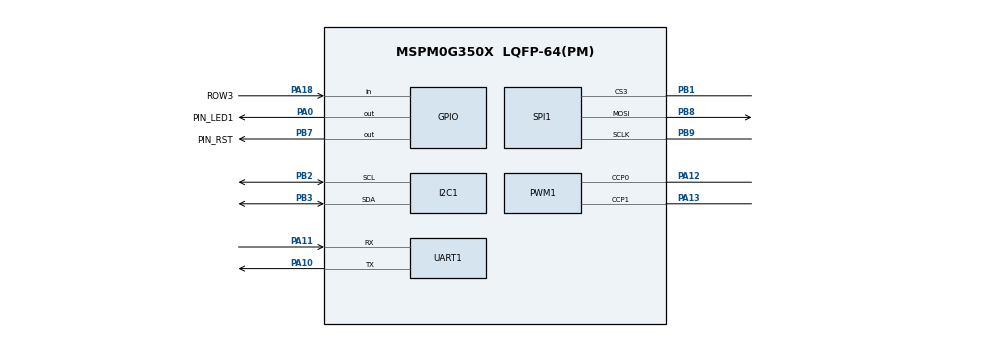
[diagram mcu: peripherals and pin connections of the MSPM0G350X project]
/**
 * @cliArgs --device "MSPM0G350X" --package "LQFP-64(PM)" --part "Default" --product "mspm0_sdk@2.01.00.03"
 * @versions {"tool":"1.20.0+3587"}
 */

/**
 * Import the modules used in this configuration.
 */
const GPIO   = scripting.addModule("/ti/driverlib/GPIO", {}, false);
const GPIO1  = GPIO.addInstance();
const GPIO2  = GPIO.addInstance();
const GPIO3  = GPIO.addInstance();
const GPIO4  = GPIO.addInstance();
const GPIO5  = GPIO.addInstance();
const GPIO6  = GPIO.addInstance();
const GPIO7  = GPIO.addInstance();
const GPIO8  = GPIO.addInstance();
const GPIO9  = GPIO.addInstance();
const GPIO10 = GPIO.addInstance();
const GPIO11 = GPIO.addInstance();
const I2C    = scripting.addModule("/ti/driverlib/I2C", {}, false);
const I2C1   = I2C.addInstance();
const PWM    = scripting.addModule("/ti/driverlib/PWM", {}, false);
const PWM1   = PWM.addInstance();
const SPI    = scripting.addModule("/ti/driverlib/SPI", {}, false);
const SPI1   = SPI.addInstance();
const SYSCTL = scripting.addModule("/ti/driverlib/SYSCTL");
const TIMER  = scripting.addModule("/ti/driverlib/TIMER", {}, false);
const TIMER1 = TIMER.addInstance();
const TIMER2 = TIMER.addInstance();
const TIMER3 = TIMER.addInstance();
const TIMER4 = TIMER.addInstance();
const TIMER5 = TIMER.addInstance();
const UART   = scripting.addModule("/ti/driverlib/UART", {}, false);
const UART1  = UART.addInstance();

/**
 * Write custom configuration values to the imported modules.
 */
GPIO1.$name                              = "GPIO_LED_2";
GPIO1.port                               = "PORTB";
GPIO1.associatedPins.create(3);
GPIO1.associatedPins[0].internalResistor = "PULL_UP";
GPIO1.associatedPins[0].assignedPin      = "27";
GPIO1.associatedPins[0].$name            = "PIN_LED_GREEN";
GPIO1.associatedPins[1].$name            = "PIN_LED_BLUE";
GPIO1.associatedPins[1].assignedPin      = "22";
GPIO1.associatedPins[2].$name            = "PIN_LED_RED";
GPIO1.associatedPins[2].assignedPin      = "26";

const Board = scripting.addModule("/ti/driverlib/Board", {}, false);

GPIO2.$name                          = "GPIO_CTRL";
GPIO2.associatedPins.create(2);
GPIO2.associatedPins[0].$name        = "PIN_RST";
GPIO2.associatedPins[0].initialValue = "SET";
GPIO2.associatedPins[0].assignedPort = "PORTB";
GPIO2.associatedPins[0].assignedPin  = "7";
GPIO2.associatedPins[0].pin.$assign  = "PB7";
GPIO2.associatedPins[1].$name        = "DC";
GPIO2.associatedPins[1].assignedPort = "PORTB";
GPIO2.associatedPins[1].assignedPin  = "6";

GPIO3.$name                          = "GPIO_BEEP";
GPIO3.port                           = "PORTB";
GPIO3.associatedPins[0].$name        = "PIN_0";
GPIO3.associatedPins[0].initialValue = "SET";
GPIO3.associatedPins[0].assignedPin  = "19";

GPIO4.port                               = "PORTB";
GPIO4.$name                              = "GPIO_BUTTON2";
GPIO4.associatedPins[0].assignedPin      = "21";
GPIO4.associatedPins[0].direction        = "INPUT";
GPIO4.associatedPins[0].$name            = "PIN_S2";
GPIO4.associatedPins[0].internalResistor = "PULL_UP";

GPIO5.$name                          = "GPIO_Encoder";
GPIO5.associatedPins.create(4);
GPIO5.associatedPins[0].direction    = "INPUT";
GPIO5.associatedPins[0].assignedPort = "PORTA";
GPIO5.associatedPins[0].interruptEn  = true;
GPIO5.associatedPins[0].polarity     = "RISE";
GPIO5.associatedPins[0].assignedPin  = "15";
GPIO5.associatedPins[0].$name        = "PIN_Forward_Right_A";
GPIO5.associatedPins[1].direction    = "INPUT";
GPIO5.associatedPins[1].assignedPort = "PORTA";
GPIO5.associatedPins[1].$name        = "PIN_Forward_Right_B";
GPIO5.associatedPins[1].assignedPin  = "22";
GPIO5.associatedPins[2].direction    = "INPUT";
GPIO5.associatedPins[2].assignedPort = "PORTA";
GPIO5.associatedPins[2].assignedPin  = "28";
GPIO5.associatedPins[2].interruptEn  = true;
GPIO5.associatedPins[2].polarity     = "RISE";
GPIO5.associatedPins[2].$name        = "PIN_Forward_Left_A";
GPIO5.associatedPins[3].direction    = "INPUT";
GPIO5.associatedPins[3].assignedPort = "PORTA";
GPIO5.associatedPins[3].assignedPin  = "31";
GPIO5.associatedPins[3].$name        = "PIN_Forward_Left_B";

GPIO6.$name                         = "GPIO_MOTOR";
GPIO6.port                          = "PORTB";
GPIO6.associatedPins.create(4);
GPIO6.associatedPins[0].$name       = "PIN_AIN1";
GPIO6.associatedPins[0].assignedPin = "0";
GPIO6.associatedPins[1].$name       = "PIN_AIN2";
GPIO6.associatedPins[1].assignedPin = "16";
GPIO6.associatedPins[2].$name       = "PIN_BIN1";
GPIO6.associatedPins[2].assignedPin = "15";
GPIO6.associatedPins[3].$name       = "PIN_BIN2";
GPIO6.associatedPins[3].assignedPin = "17";

GPIO7.$name                         = "GPIO_LED1";
GPIO7.associatedPins[0].$name       = "PIN_LED1";
GPIO7.associatedPins[0].pin.$assign = "PA0";

GPIO8.$name                         = "GPIO_GRAY_SERIAL";
GPIO8.port                          = "PORTA";
GPIO8.associatedPins.create(2);
GPIO8.associatedPins[0].$name       = "PIN_CLK";
GPIO8.associatedPins[0].assignedPin = "24";
GPIO8.associatedPins[1].$name       = "PIN_FOWARD_DAT";
GPIO8.associatedPins[1].direction   = "INPUT";
GPIO8.associatedPins[1].assignedPin = "1";

GPIO9.$name                          = "GPIO_COL";
GPIO9.port                           = "PORTA";
GPIO9.associatedPins.create(4);
GPIO9.associatedPins[0].$name        = "COL1";
GPIO9.associatedPins[0].initialValue = "SET";
GPIO9.associatedPins[0].assignedPin  = "25";
GPIO9.associatedPins[1].$name        = "COL2";
GPIO9.associatedPins[1].initialValue = "SET";
GPIO9.associatedPins[1].assignedPin  = "8";
GPIO9.associatedPins[2].$name        = "COL3";
GPIO9.associatedPins[2].initialValue = "SET";
GPIO9.associatedPins[2].assignedPin  = "26";
GPIO9.associatedPins[3].$name        = "COL4";
GPIO9.associatedPins[3].initialValue = "SET";
GPIO9.associatedPins[3].assignedPin  = "27";

GPIO10.$name                              = "GPIO_ROW";
GPIO10.associatedPins.create(4);
GPIO10.associatedPins[0].$name            = "ROW1";
GPIO10.associatedPins[0].direction        = "INPUT";
GPIO10.associatedPins[0].internalResistor = "PULL_UP";
GPIO10.associatedPins[0].assignedPin      = "24";
GPIO10.associatedPins[0].assignedPort     = "PORTB";
GPIO10.associatedPins[1].$name            = "ROW2";
GPIO10.associatedPins[1].direction        = "INPUT";
GPIO10.associatedPins[1].internalResistor = "PULL_UP";
GPIO10.associatedPins[1].assignedPin      = "18";
GPIO10.associatedPins[1].assignedPort     = "PORTB";
GPIO10.associatedPins[2].$name            = "ROW3";
GPIO10.associatedPins[2].direction        = "INPUT";
GPIO10.associatedPins[2].internalResistor = "PULL_UP";
GPIO10.associatedPins[2].assignedPort     = "PORTA";
GPIO10.associatedPins[2].assignedPin      = "18";
GPIO10.associatedPins[2].pin.$assign      = "PA18";
GPIO10.associatedPins[3].direction        = "INPUT";
GPIO10.associatedPins[3].internalResistor = "PULL_UP";
GPIO10.associatedPins[3].$name            = "ROW4";
GPIO10.associatedPins[3].assignedPort     = "PORTA";
GPIO10.associatedPins[3].assignedPin      = "17";

GPIO11.$name                          = "GPIO_MYLED";
GPIO11.associatedPins[0].$name        = "PIN_LED";
GPIO11.associatedPins[0].assignedPort = "PORTB";
GPIO11.associatedPins[0].assignedPin  = "4";

I2C1.$name                             = "I2C_MPU6050";
I2C1.basicEnableController             = true;
I2C1.intController                     = ["ARBITRATION_LOST","NACK","RXFIFO_TRIGGER","RX_DONE","TX_DONE"];
I2C1.peripheral.sdaPin.$assign         = "PB3";
I2C1.peripheral.sclPin.$assign         = "PB2";
I2C1.sdaPinConfig.hideOutputInversion  = scripting.forceWrite(false);
I2C1.sdaPinConfig.onlyInternalResistor = scripting.forceWrite(false);
I2C1.sdaPinConfig.passedPeripheralType = scripting.forceWrite("Digital");
I2C1.sdaPinConfig.$name                = "ti_driverlib_gpio_GPIOPinGeneric7";
I2C1.sclPinConfig.hideOutputInversion  = scripting.forceWrite(false);
I2C1.sclPinConfig.onlyInternalResistor = scripting.forceWrite(false);
I2C1.sclPinConfig.passedPeripheralType = scripting.forceWrite("Digital");
I2C1.sclPinConfig.$name                = "ti_driverlib_gpio_GPIOPinGeneric8";

PWM1.$name                              = "PWM_MOTOR";
PWM1.timerCount                         = 3200;
PWM1.peripheral.$assign                 = "TIMG0";
PWM1.peripheral.ccp0Pin.$assign         = "PA12";
PWM1.peripheral.ccp1Pin.$assign         = "PA13";
PWM1.PWM_CHANNEL_0.$name                = "ti_driverlib_pwm_PWMTimerCC0";
PWM1.PWM_CHANNEL_1.$name                = "ti_driverlib_pwm_PWMTimerCC1";
PWM1.ccp0PinConfig.$name                = "ti_driverlib_gpio_GPIOPinGeneric2";
PWM1.ccp0PinConfig.direction            = scripting.forceWrite("OUTPUT");
PWM1.ccp0PinConfig.hideOutputInversion  = scripting.forceWrite(false);
PWM1.ccp0PinConfig.onlyInternalResistor = scripting.forceWrite(false);
PWM1.ccp0PinConfig.passedPeripheralType = scripting.forceWrite("Digital");
PWM1.ccp1PinConfig.$name                = "ti_driverlib_gpio_GPIOPinGeneric3";
PWM1.ccp1PinConfig.direction            = scripting.forceWrite("OUTPUT");
PWM1.ccp1PinConfig.hideOutputInversion  = scripting.forceWrite(false);
PWM1.ccp1PinConfig.onlyInternalResistor = scripting.forceWrite(false);
PWM1.ccp1PinConfig.passedPeripheralType = scripting.forceWrite("Digital");

SPI1.$name                      = "SPI_0";
SPI1.enableCDMode               = true;
SPI1.direction                  = "PICO";
SPI1.frameFormat                = "MOTO3";
SPI1.peripheral.$assign         = "SPI1";
SPI1.peripheral.sclkPin.$assign = "PB9";
SPI1.peripheral.mosiPin.$assign = "PB8";
SPI1.peripheral.cs3Pin.$assign  = "PB1";
SPI1.sclkPinConfig.$name        = "ti_driverlib_gpio_GPIOPinGeneric0";
SPI1.mosiPinConfig.$name        = "ti_driverlib_gpio_GPIOPinGeneric1";
SPI1.cs3PinConfig.$name         = "ti_driverlib_gpio_GPIOPinGeneric4";

SYSCTL.forceDefaultClkConfig = true;
SYSCTL.clockTreeEn           = true;

TIMER1.$name              = "TIMER_CarCTRL";
TIMER1.timerMode          = "PERIODIC";
TIMER1.interrupts         = ["ZERO"];
TIMER1.interruptPriority  = "1";
TIMER1.timerClkPrescale   = 32;
TIMER1.timerPeriod        = "10ms";
TIMER1.peripheral.$assign = "TIMG8";

TIMER2.timerMode          = "PERIODIC";
TIMER2.timerClkDiv        = 8;
TIMER2.timerClkPrescale   = 32;
TIMER2.interrupts         = ["ZERO"];
TIMER2.$name              = "TIMER_CarCTRL_Alternative";
TIMER2.timerPeriod        = "10 ms";
TIMER2.interruptPriority  = "1";
TIMER2.peripheral.$assign = "TIMG7";

TIMER3.$name              = "TIMER_DingShiQi";
TIMER3.interrupts         = ["ZERO"];
TIMER3.timerClkDiv        = 8;
TIMER3.timerPeriod        = "1.6s";
TIMER3.timerClkPrescale   = 200;
TIMER3.peripheral.$assign = "TIMG6";

TIMER4.$name              = "TIMER_ShengGuang";
TIMER4.timerClkDiv        = 8;
TIMER4.timerClkPrescale   = 32;
TIMER4.timerPeriod        = "500 ms";
TIMER4.interrupts         = ["ZERO"];
TIMER4.peripheral.$assign = "TIMA0";

TIMER5.$name            = "TIMER_JiaJianSu";
TIMER5.timerClkDiv      = 8;
TIMER5.timerClkPrescale = 200;
TIMER5.timerPeriod      = "100 ms";
TIMER5.interrupts       = ["ZERO"];

UART1.$name                    = "UART_0";
UART1.enabledInterrupts        = ["RX"];
UART1.peripheral.rxPin.$assign = "PA11";
UART1.peripheral.txPin.$assign = "PA10";
UART1.txPinConfig.$name        = "ti_driverlib_gpio_GPIOPinGeneric5";
UART1.rxPinConfig.$name        = "ti_driverlib_gpio_GPIOPinGeneric6";

/**
 * Pinmux solution for unlocked pins/peripherals. This ensures that minor changes to the automatic solver in a future
 * version of the tool will not impact the pinmux you originally saw.  These lines can be completely deleted in order to
 * re-solve from scratch.
 */
GPIO1.associatedPins[0].pin.$suggestSolution  = "PB27";
GPIO1.associatedPins[1].pin.$suggestSolution  = "PB22";
GPIO1.associatedPins[2].pin.$suggestSolution  = "PB26";
Board.peripheral.$suggestSolution             = "DEBUGSS";
Board.peripheral.swclkPin.$suggestSolution    = "PA20";
Board.peripheral.swdioPin.$suggestSolution    = "PA19";
GPIO2.associatedPins[1].pin.$suggestSolution  = "PB6";
GPIO3.associatedPins[0].pin.$suggestSolution  = "PB19";
GPIO4.associatedPins[0].pin.$suggestSolution  = "PB21";
GPIO5.associatedPins[0].pin.$suggestSolution  = "PA15";
GPIO5.associatedPins[1].pin.$suggestSolution  = "PA22";
GPIO5.associatedPins[2].pin.$suggestSolution  = "PA28";
GPIO5.associatedPins[3].pin.$suggestSolution  = "PA31";
GPIO6.associatedPins[0].pin.$suggestSolution  = "PB0";
GPIO6.associatedPins[1].pin.$suggestSolution  = "PB16";
GPIO6.associatedPins[2].pin.$suggestSolution  = "PB15";
GPIO6.associatedPins[3].pin.$suggestSolution  = "PB17";
GPIO8.associatedPins[0].pin.$suggestSolution  = "PA24";
GPIO8.associatedPins[1].pin.$suggestSolution  = "PA1";
GPIO9.associatedPins[0].pin.$suggestSolution  = "PA25";
GPIO9.associatedPins[1].pin.$suggestSolution  = "PA8";
GPIO9.associatedPins[2].pin.$suggestSolution  = "PA26";
GPIO9.associatedPins[3].pin.$suggestSolution  = "PA27";
GPIO10.associatedPins[0].pin.$suggestSolution = "PB24";
GPIO10.associatedPins[1].pin.$suggestSolution = "PB18";
GPIO10.associatedPins[3].pin.$suggestSolution = "PA17";
GPIO11.associatedPins[0].pin.$suggestSolution = "PB4";
I2C1.peripheral.$suggestSolution              = "I2C1";
TIMER5.peripheral.$suggestSolution            = "TIMA1";
UART1.peripheral.$suggestSolution             = "UART0";
